# STM32H7S7xx register map
File version: 1.0
Registers are 32-bit, read-write, reset 0x0 unless marked. A register's access mark holds for its fields unless they carry their own. Offsets are from the block's base; [hi:lo] are bit positions; {n}, {i} and the like mark numbered series; 'fields as' and 'values as' point back to an identical list.

## FLASH — FLASH Registers
Base 0x52002000
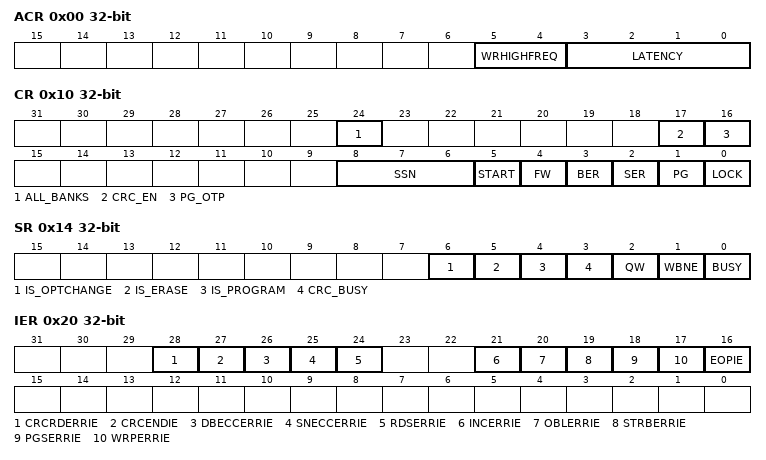
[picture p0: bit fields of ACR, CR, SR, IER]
0x00 ACR — FLASH access control register
  [5:4] WRHIGHFREQ — Flash signal delay
  [3:0] LATENCY — Read Latency
    0=FLASH Zero wait state; 1=FLASH One wait state; 2=FLASH Two wait states; 3=FLASH Three wait states; 4=FLASH Four wait states; 5=FLASH Five wait state; 6=FLASH Six wait state; 7=FLASH Seven wait states
0x04 KEYR — FLASH control key register
  [31:0] CUKEY — Control unlock key
0x10 CR — FLASH control register
  [24] ALL_BANKS — All banks select bit
  [17] CRC_EN — CRC enable
  [16] PG_OTP — Program Enable for OTP Area
  [8:6] SSN — Sector erase selection number
  [5] START — Erase start control bit
  [4] FW — Force write
  [3] BER — Bank erase request
  [2] SER — Sector erase request
  [1] PG — Internal buffer control bit
  [0] LOCK — Configuration lock bit
0x14 SR — FLASH status register
  [6] IS_OPTCHANGE — Is an option change
  [5] IS_ERASE — Is an erase
  [4] IS_PROGRAM
  [3] CRC_BUSY — CRC busy flag
  [2] QW — Wait queue flag
  [1] WBNE — Write buffer not empty flag
  [0] BUSY — Busy flag
0x20 IER — FLASH interrupt enable register
  [28] CRCRDERRIE — CRC read error interrupt enable bit
  [27] CRCENDIE — CRC end of calculation interrupt enable bit
  [26] DBECCERRIE — ECC double detection error interrupt enable bit
  [25] SNECCERRIE — ECC single correction error interrupt enable bit
  [24] RDSERRIE — Read security error interrupt enable bit
  [21] INCERRIE — Inconsistency error interrupt enable bit
  [20] OBLERRIE — Option byte loading error interrupt enable bit
  [19] STRBERRIE — Strobe error interrupt enable bit
  [18] PGSERRIE — Programming sequence error interrupt enable bit
  [17] WRPERRIE — Write protection error interrupt enable bit
  [16] EOPIE — End of program interrupt enable bit
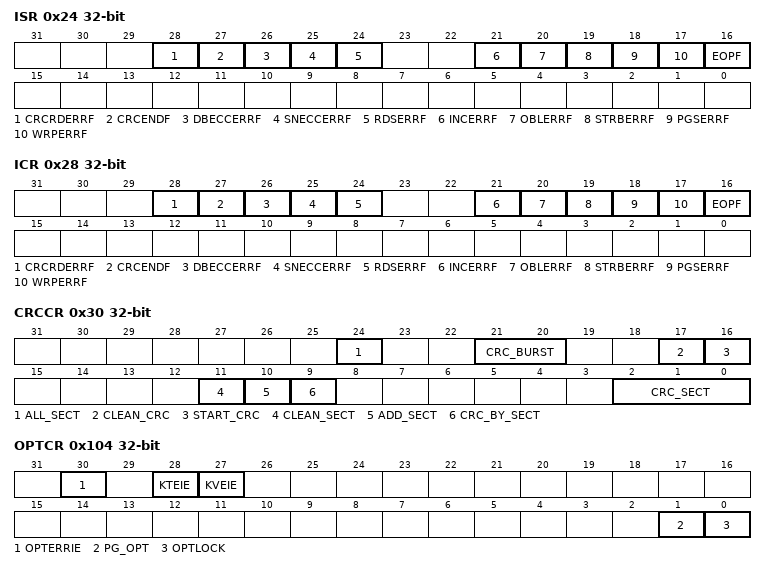
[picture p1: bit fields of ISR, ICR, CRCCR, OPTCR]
0x24 ISR — FLASH interrupt status register
  [28] CRCRDERRF — CRC read error flag
  [27] CRCENDF — CRC end of calculation flag
  [26] DBECCERRF — ECC double error flag
  [25] SNECCERRF — ECC single error flag
  [24] RDSERRF — Read security error flag
  [21] INCERRF — Inconsistency error flag
  [20] OBLERRF — Option byte loading error flag
  [19] STRBERRF — Strobe error flag
  [18] PGSERRF — Programming sequence error flag
  [17] WRPERRF — Write protection error flag
  [16] EOPF — End of program flag
0x28 ICR — FLASH interrupt clear register
  [28] CRCRDERRF — CRC read error flag clear
  [27] CRCENDF — CRC end flag clear
  [26] DBECCERRF — ECC double error flag clear
  [25] SNECCERRF — ECC single error flag clear
  [24] RDSERRF — Read security error flag clear
  [21] INCERRF — Inconsistency error flag clear
  [20] OBLERRF — Option byte loading error flag clear
  [19] STRBERRF — Strobe error flag clear
  [18] PGSERRF — Programming sequence error flag clear
  [17] WRPERRF — Write protection error flag clear
  [16] EOPF — End of program flag clear
0x30 CRCCR — FLASH CRC control register
  [24] ALL_SECT — All sectors selection
  [21:20] CRC_BURST — CRC burst size
  [17] CLEAN_CRC — CRC clear bit
  [16] START_CRC — CRC start bit
  [11] CLEAN_SECT — CRC sector list clear bit
  [10] ADD_SECT — CRC sector select bit
  [9] CRC_BY_SECT — CRC sector mode select bit
  [2:0] CRC_SECT — CRC sector number
0x34 CRCSADDR — FLASH CRC start address register
  [16:6] CRC_START_ADDRESS
0x38 CRCEADDR — FLASH CRC end address register
  [16:6] CRC_END_ADDRESS
0x3C CRCDATAR — FLASH CRC data register
  [31:0] CRC_DATA — CRC result
0x40 ECCSFADDR — FLASH ECC single fail address register
  [31:0] SEC_FADD — ECC single error correction fail address
0x44 ECCDFADDR — FLASH ECC double fail address register
  [31:0] DED_FADD — ECC double error detection fail address
0x100 OPTKEYR — FLASH options key register
  [31:0] OCUKEY — Options configuration unlock key
0x104 OPTCR — FLASH options control register
  [30] OPTERRIE — Options byte change error interrupt enable bit
  [28] KTEIE — Key transfer error interrupt enable bit
  [27] KVEIE — Key valid error interrupt enable bit
  [1] PG_OPT — Program options
  [0] OPTLOCK — Options lock
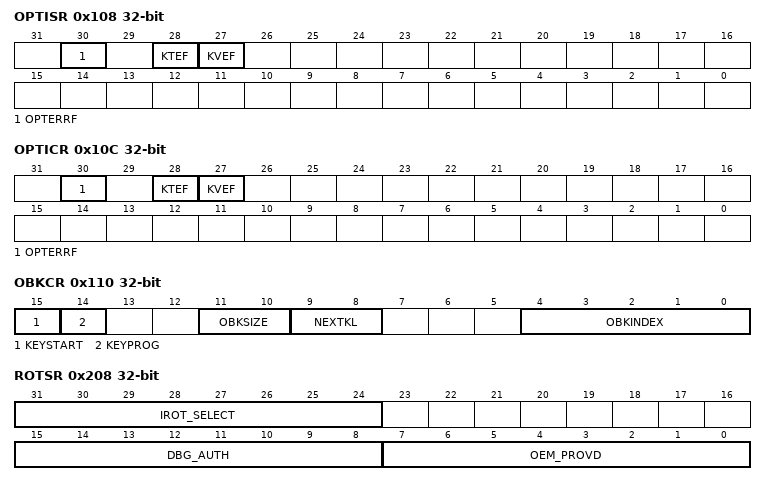
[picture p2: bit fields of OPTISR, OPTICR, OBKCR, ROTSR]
0x108 OPTISR — FLASH options interrupt status register
  [30] OPTERRF — Options byte change error flag
  [28] KTEF — Key transfer error flag
  [27] KVEF — Key valid error flag
0x10C OPTICR — FLASH options interrupt clear register
  [30] OPTERRF — Options byte change error flag clear
  [28] KTEF — Key transfer error flag clear
  [27] KVEF — Key valid error flag clear
0x110 OBKCR — FLASH option byte key control register
  [15] KEYSTART — Key option start
  [14] KEYPROG — Key program
  [11:10] OBKSIZE — Option byte key size
  [9:8] NEXTKL — Next key level
  [4:0] OBKINDEX — Option byte key index
{0x118+4i} OBKDR{i} (i=0..7) — FLASH option bytes key data register
  [31:0] OBKDATA — Option byte key data
0x200 NVSR — FLASH non-volatile status register
  [7:0] NVSTATE — Non-volatile state
0x204 NVSRP — FLASH security status register programming
  [7:0] NVSTATE — Non-volatile state
0x208 ROTSR — FLASH RoT status register
  [31:24] IROT_SELECT — iRoT selection
  [15:8] DBG_AUTH — Debug authentication method
  [7:0] OEM_PROVD — OEM provisioned state
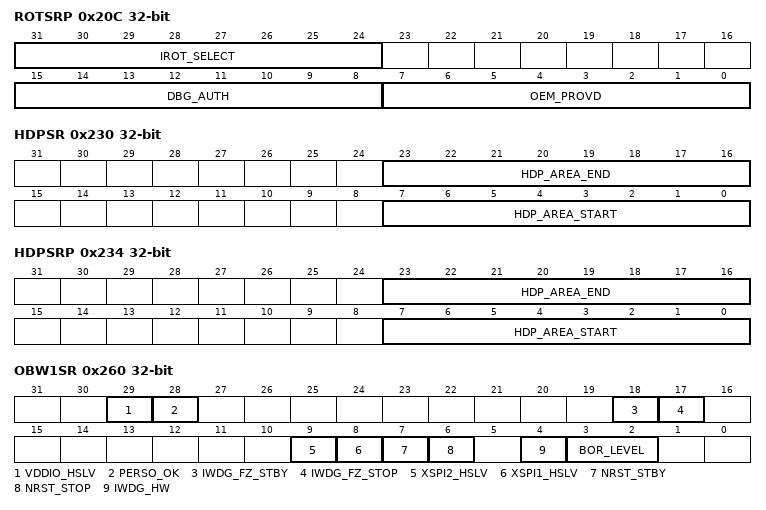
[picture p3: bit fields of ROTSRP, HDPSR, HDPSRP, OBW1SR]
0x20C ROTSRP — FLASH RoT status register programming
  fields as ROTSR
0x210 OTPLSR — FLASH OTP lock status register
  [15:0] OTPL — OTP lock n (n=0 to 15)
0x214 OTPLSRP — FLASH OTP lock status programming register
  [15:0] OTPL — OTP lock n (n=0 to 15)
0x218 WRPSR — FLASH write protection status register
  [7:0] WRPS — Write protection for sector n (n=0 to 7)
0x21C WRPSRP — FLASH write protection status register programming
  [7:0] WRPS — Write protection for sector n (n=0 to 7)
0x230 HDPSR — FLASH hide protection status register
  [23:16] HDP_AREA_END — Hide protection user flash area end
  [7:0] HDP_AREA_START — Hide protection user flash area start
0x234 HDPSRP — FLASH hide protection status register programming
  fields as HDPSR
0x250 EPOCHSR — FLASH epoch status register
  [23:0] EPOCH
0x254 EPOCHSRP — FLASH epoch status register programming
  [23:0] EPOCH
0x260 OBW1SR — FLASH option byte word 1 status register
  [29] VDDIO_HSLV — I/O High-speed at low voltage
  [28] PERSO_OK — Personnalization OK
  [18] IWDG_FZ_STBY — IWDG Standby mode freeze
  [17] IWDG_FZ_STOP — IWDG Stop mode freeze
  [9] XSPI2_HSLV — XSPI2 High-speed at low voltage
  [8] XSPI1_HSLV — XSPI1 High-speed at low voltage
  [7] NRST_STBY — Reset on standby mode
  [6] NRST_STOP — Reset on stop mode
  [4] IWDG_HW — Independent watchdog HW control
  [3:2] BOR_LEVEL — Brownout level
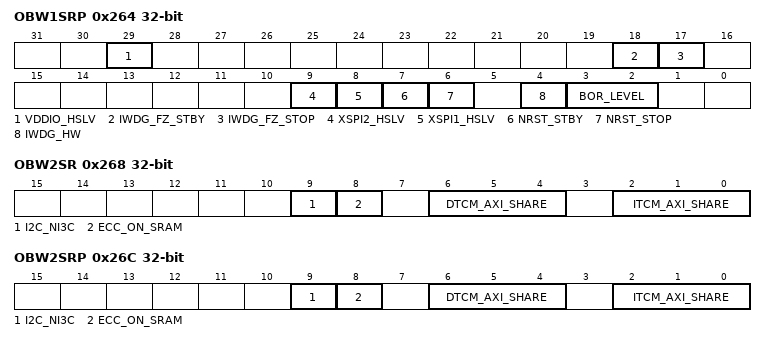
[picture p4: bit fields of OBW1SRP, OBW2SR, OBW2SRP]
0x264 OBW1SRP — FLASH option byte word 1 status register programming
  [29] VDDIO_HSLV — I/O High-speed at low voltage
  [18] IWDG_FZ_STBY — IWDG Standby mode freeze
  [17] IWDG_FZ_STOP — IWDG Stop mode freeze
  [9] XSPI2_HSLV — XSPI2 High-speed at low voltage
  [8] XSPI1_HSLV — XSPI1 High-speed at low voltage
  [7] NRST_STBY — Reset on standby mode
  [6] NRST_STOP — Reset on stop mode
  [4] IWDG_HW — Independent watchdog HW control
  [3:2] BOR_LEVEL — Brownout level
0x268 OBW2SR — FLASH option byte word 2 status register
  [9] I2C_NI3C — I2C Not I3C
  [8] ECC_ON_SRAM
  [6:4] DTCM_AXI_SHARE
  [2:0] ITCM_AXI_SHARE
0x26C OBW2SRP — FLASH option byte word 2 status register programming
  fields as OBW2SR
